# MKM34Z7 register map
Vendor: Freescale Semiconductor, Inc.; Series: Kinetis_M; File version: 1.6
CPU: CM0PLUS r0p0, little endian, no MPU, no FPU, VTOR, 2 interrupt priority bits
Registers are 32-bit, read-write, reset 0x0 unless marked. A register's access mark holds for its fields unless they carry their own. Offsets are from the block's base; [hi:lo] are bit positions; {n}, {i} and the like mark numbered series.

## PMC — Power Management Controller
Base 0x4007D000; register names take the prefix PMC_
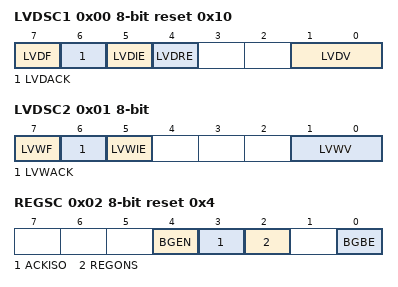
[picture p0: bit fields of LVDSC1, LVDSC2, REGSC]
0x00 LVDSC1 8-bit reset 0x10 — Low Voltage Detect Status And Control 1 register
  [7] LVDF ro — Low-Voltage Detect Flag
    0=Low-voltage event not detected; 1=Low-voltage event detected
  [6] LVDACK wo — Low-Voltage Detect Acknowledge
  [5] LVDIE — Low-Voltage Detect Interrupt Enable
    0=Hardware interrupt disabled (use polling); 1=Request a hardware interrupt when LVDF = 1
  [4] LVDRE — Low-Voltage Detect Reset Enable
    0=LVDF does not generate hardware resets; 1=Force an MCU reset when LVDF = 1
  [1:0] LVDV — Low-Voltage Detect Voltage Select
    0=Low trip point selected (V LVD = V LVDL ); 1=High trip point selected (V LVD = V LVDH )
0x01 LVDSC2 8-bit — Low Voltage Detect Status And Control 2 register
  [7] LVWF ro — Low-Voltage Warning Flag
    0=Low-voltage warning event not detected; 1=Low-voltage warning event detected
  [6] LVWACK wo — Low-Voltage Warning Acknowledge
  [5] LVWIE — Low-Voltage Warning Interrupt Enable
    0=Hardware interrupt disabled (use polling); 1=Request a hardware interrupt when LVWF = 1
  [1:0] LVWV — Low-Voltage Warning Voltage Select
    0=Low trip point selected (VLVW = VLVW1); 1=Mid 1 trip point selected (VLVW = VLVW2); 2=Mid 2 trip point selected (VLVW = VLVW3); 3=High trip point selected (VLVW = VLVW4)
0x02 REGSC 8-bit reset 0x4 — Regulator Status And Control register
  [4] BGEN — Bandgap Enable In VLPx Operation
    0=Bandgap voltage reference is disabled in VLPx , and VLLSx modes; 1=Bandgap voltage reference is enabled in VLPx , and VLLSx modes
  [3] ACKISO — Acknowledge Isolation
    0=Peripherals and I/O pads are in normal run state; 1=Certain peripherals and I/O pads are in an isolated and latched state
  [2] REGONS ro — Regulator In Run Regulation Status
    0=Regulator is in stop regulation or in transition to/from it; 1=Regulator is in run regulation
  [0] BGBE — Bandgap Buffer Enable
    0=Bandgap buffer not enabled; 1=Bandgap buffer enabled

## SMC — System Mode Controller
Base 0x4007E000; register names take the prefix SMC_
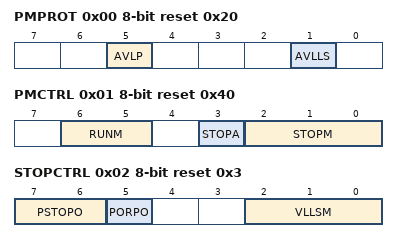
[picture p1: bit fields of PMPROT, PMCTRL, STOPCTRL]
0x00 PMPROT 8-bit reset 0x20 — Power Mode Protection register
  [5] AVLP — Allow Very-Low-Power Modes
    0=VLPR, VLPW, and VLPS are not allowed; 1=VLPR, VLPW, and VLPS are allowed
  [1] AVLLS — Allow Very-Low-Leakage Stop Mode
    0=Any VLLSx mode is not allowed; 1=Any VLLSx mode is allowed
0x01 PMCTRL 8-bit reset 0x40 — Power Mode Control register
  [6:5] RUNM — Run Mode Control
    0=Normal Run mode (RUN); 2=Very-Low-Power Run mode (VLPR)
  [3] STOPA ro — Stop Aborted
    0=The previous stop mode entry was successsful; 1=The previous stop mode entry was aborted
  [2:0] STOPM — Stop Mode Control
    0=Normal Stop (STOP); 2=Very-Low-Power Stop (VLPS); 4=Very-Low-Leakage Stop (VLLSx); 6=Reseved
0x02 STOPCTRL 8-bit reset 0x3 — Stop Control Register
  [7:6] PSTOPO — Partial Stop Option
    0=STOP - Normal Stop mode; 1=PSTOP1 - Partial Stop with both system and bus clocks disabled; 2=PSTOP2 - Partial Stop with system clock disabled and bus clock enabled
  [5] PORPO — POR Power Option
    0=POR detect circuit is enabled in VLLS0; 1=POR detect circuit is disabled in VLLS0
  [2:0] VLLSM — VLLS Mode Control
    {v}=VLLS{v} (v=0..3)
0x03 PMSTAT 8-bit ro reset 0x4 — Power Mode Status register
  [7:0] PMSTAT — Power Mode Status

## SystemControl — System Control Block
Base 0xE000E000; register names take the prefix SCB_
0x08 ACTLR ro — Auxiliary Control Register,
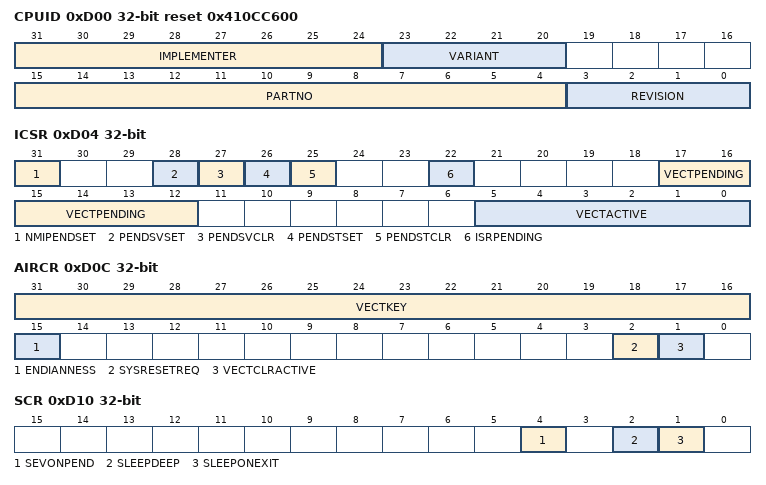
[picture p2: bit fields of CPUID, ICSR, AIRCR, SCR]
0xD00 CPUID ro reset 0x410CC600 — CPUID Base Register
  [31:24] IMPLEMENTER — Implementer code
  [23:20] VARIANT — Indicates processor revision: 0x2 = Revision 2
  [15:4] PARTNO — Indicates part number
  [3:0] REVISION — Indicates patch release: 0x0 = Patch 0
0xD04 ICSR — Interrupt Control and State Register
  [31] NMIPENDSET
    0=write: no effect; read: NMI exception is not pending; 1=write: changes NMI exception state to pending; read: NMI exception is pending
  [28] PENDSVSET
    0=write: no effect; read: PendSV exception is not pending; 1=write: changes PendSV exception state to pending; read: PendSV exception is pending
  [27] PENDSVCLR wo
    0=no effect; 1=removes the pending state from the PendSV exception
  [26] PENDSTSET
    0=write: no effect; read: SysTick exception is not pending; 1=write: changes SysTick exception state to pending; read: SysTick exception is pending
  [25] PENDSTCLR wo
    0=no effect; 1=removes the pending state from the SysTick exception
  [22] ISRPENDING ro
  [17:12] VECTPENDING ro — Exception number of the highest priority pending enabled exception
  [5:0] VECTACTIVE ro — Active exception number
0xD08 VTOR — Vector Table Offset Register
  [31:7] TBLOFF — Vector table base offset
0xD0C AIRCR — Application Interrupt and Reset Control Register
  [31:16] VECTKEY — Register key
  [15] ENDIANNESS ro
    0=Little-endian; 1=Big-endian
  [2] SYSRESETREQ wo
    0=no system reset request; 1=asserts a signal to the outer system that requests a reset
  [1] VECTCLRACTIVE wo
0xD10 SCR — System Control Register
  [4] SEVONPEND
    0=only enabled interrupts or events can wakeup the processor, disabled interrupts are excluded; 1=enabled events and all interrupts, including disabled interrupts, can wakeup the processor
  [2] SLEEPDEEP
    0=sleep; 1=deep sleep
  [1] SLEEPONEXIT
    0=o not sleep when returning to Thread mode; 1=enter sleep, or deep sleep, on return from an ISR
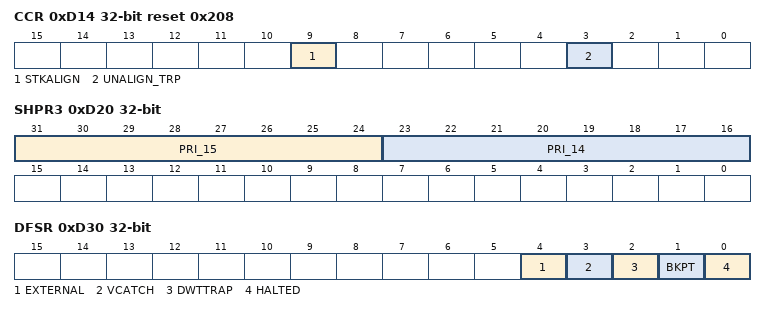
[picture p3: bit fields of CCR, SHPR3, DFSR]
0xD14 CCR ro reset 0x208 — Configuration and Control Register
  [9] STKALIGN — Indicates stack alignment on exception entry
  [3] UNALIGN_TRP — Always reads as one, indicates that all unaligned accesses generate a HardFault
0xD1C SHPR2 — System Handler Priority Register 2
  [31:24] PRI_11 — Priority of system handler 11, SVCall
0xD20 SHPR3 — System Handler Priority Register 3
  [31:24] PRI_15 — Priority of system handler 15, SysTick exception
  [23:16] PRI_14 — Priority of system handler 14, PendSV
0xD24 SHCSR — System Handler Control and State Register
  [15] SVCALLPENDED
    0=exception is not pending; 1=exception is pending
0xD30 DFSR — Debug Fault Status Register
  [4] EXTERNAL
    0=No EDBGRQ debug event; 1=EDBGRQ debug event
  [3] VCATCH
    0=No Vector catch triggered; 1=Vector catch triggered
  [2] DWTTRAP
    0=No current debug events generated by the DWT; 1=At least one current debug event generated by the DWT
  [1] BKPT
    0=No current breakpoint debug event; 1=At least one current breakpoint debug event
  [0] HALTED
    0=No active halt request debug event; 1=Halt request debug event active
